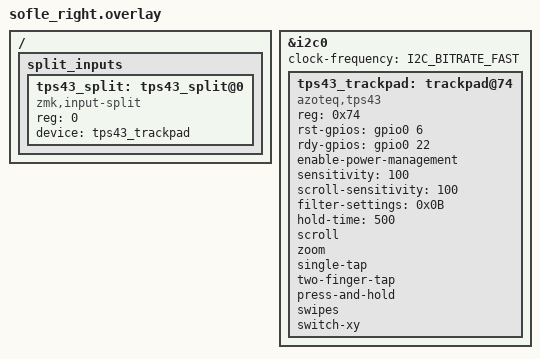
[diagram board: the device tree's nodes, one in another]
/*
 * Azoteq TPS43 trackpad, wired to the right half.
 *
 * This half no longer drives a nice!view (see build.yaml - sofle_right
 * is built without nice_view_adapter/nice_view), so the 4-pin "OLED"
 * header on the PCB (GND / VCC / SDA / SCL) is free. It is wired to the
 * nice_nano_v2's i2c0 bus, which nice_nano already pinctrl's to those
 * exact pads by default (D2 = SDA = P0.17, D3 = SCL = P0.20) - the same
 * pins nice_view_adapter would otherwise have repurposed for its SPI
 * bus, so no custom pinctrl is needed here.
 *
 * RST reuses the nice!view CS pad, D1 (P0.06), which is free on this
 * half now that there is no display. RDY uses D4 (P0.22): unlike the
 * lily58/corne builds this cannot be D21 (P0.31), because on the Sofle
 * D20/D21 are the right encoder's A/B pins.
 *
 * Wiring:
 *   TPS43 VDD -> 3V (Red)            TPS43 GND -> GND (Black)
 *   TPS43 SDA -> nice_nano D2   TPS43 SCL -> nice_nano D3
 *   TPS43 RDY -> nice_nano D4 (Blue)  TPS43 RST -> nice_nano D1 (nice!view CS pad) (White)
 */

&i2c0 {
    status = "okay";
    clock-frequency = <I2C_BITRATE_FAST>;

    tps43_trackpad: trackpad@74 {
        compatible = "azoteq,tps43";
        reg = <0x74>;
        status = "okay";

        rst-gpios = <&gpio0 6 GPIO_ACTIVE_HIGH>;
        rdy-gpios = <&gpio0 22 GPIO_ACTIVE_HIGH>;

        enable-power-management;

        sensitivity = <100>;
        scroll-sensitivity = <100>;
        filter-settings = <0x0B>;
        hold-time = <500>;

        scroll;
        zoom;
        single-tap;
        two-finger-tap;
        press-and-hold;
        swipes;

        // Uncomment/adjust after test-fitting the module, depending on
        // how it ends up mounted (rotation/mirroring vs. the datasheet
        // origin):
           switch-xy;
        // invert-x;
        // invert-y;
        // invert-scroll-y;
    };
};

/ {
    split_inputs {
        #address-cells = <1>;
        #size-cells = <0>;

        tps43_split: tps43_split@0 {
            compatible = "zmk,input-split";
            reg = <0>;
            device = <&tps43_trackpad>;
        };
    };
};
